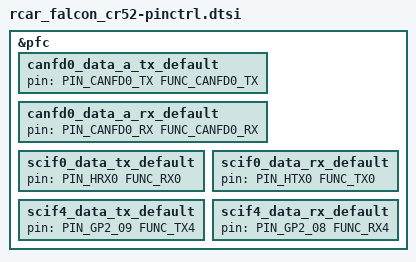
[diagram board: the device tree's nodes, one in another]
/*
 * Copyright (c) 2022 IoT.bzh
 *
 * SPDX-License-Identifier: Apache-2.0
 */

#include <dt-bindings/pinctrl/renesas/pinctrl-r8a779a0.h>

&pfc {
	canfd0_data_a_tx_default: canfd0_data_a_tx_default {
		pin = <PIN_CANFD0_TX FUNC_CANFD0_TX>;
	};

	canfd0_data_a_rx_default: canfd0_data_a_rx_default {
		pin = <PIN_CANFD0_RX FUNC_CANFD0_RX>;
	};

	scif0_data_tx_default: scif0_data_tx_default {
		pin = <PIN_HRX0 FUNC_RX0>;
	};

	scif0_data_rx_default: scif0_data_rx_default {
		pin = <PIN_HTX0 FUNC_TX0>;
	};

	scif4_data_tx_default: scif4_data_tx_default {
		pin = <PIN_GP2_09 FUNC_TX4>;
	};

	scif4_data_rx_default: scif4_data_rx_default {
		pin = <PIN_GP2_08 FUNC_RX4>;
	};
};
